# dm646x_cslr_tsif register map
Vendor: Texas Instruments
Peripheral module from a debugger description file.
Registers are 32-bit, access not given, reset 0x0 unless marked. A register's access mark holds for its fields unless they carry their own. Offsets are as the file gives them; lines under a group give offsets from that group; [hi:lo] are bit positions; {n}, {i} and the like mark numbered series; 'fields as' and 'values as' point back to an identical list; <NAME> marks a mode.

## TSIF
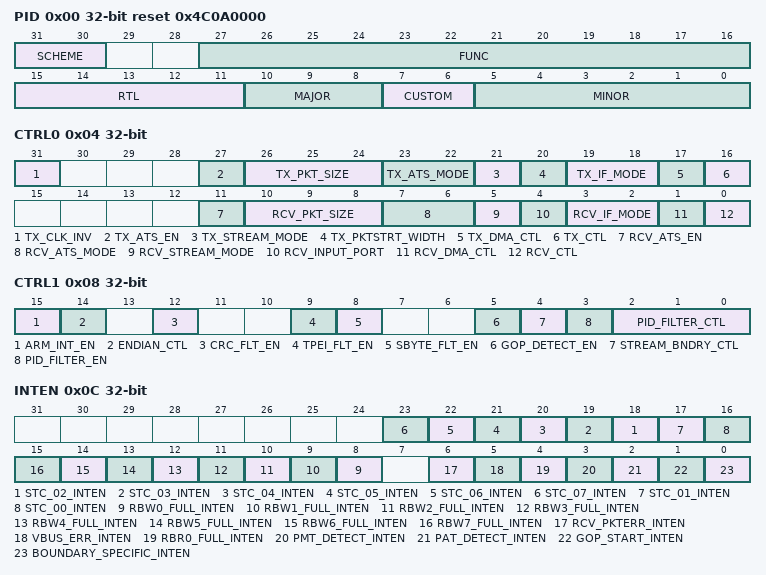
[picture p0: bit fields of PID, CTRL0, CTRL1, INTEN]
0x00 PID reset 0x4C0A0000 — SPIO PID Register
  [31:30] SCHEME ro — Used to distinguish between old scheme and current. Spare bit to encode future schemes. Fixed to be "01
  [27:16] FUNC ro — Function indicates an S/W compatible module family. If there is not level of S/W compatibility, a new Func number (and hence PID) should be assigned
  [15:11] RTL ro — Indicates RTL version
  [10:8] MAJOR ro — Local revision number which should be owned by module designer. This number should be updated for each major design change (such as bug fix, and memory size change etc ). In present design, fixed to be 0
  [7:6] CUSTOM ro — Indicates a special version for a particular device. Consequence of use may avoid use of standard chip support library (CSL). In this module, fixed to be 0.
  [5:0] MINOR ro — Local revision number which should be owned by module designer. This number should be updated for each small design change. In present design, fixed to be 0.
0x04 CTRL0 — SPIO Control Register 0
  [31] TX_CLK_INV rw — This bit controls output timing of transmit clock 0 : Data will output at falling edge of transmit clock(default) 1 : Data will output at rising edge of transmit clock Note that this bit should not be changed during transmit function is enabled
    0=INACTIVATE (Data will output at falling edge of transmit clock(default)); 1=ACTIVATE (Data will output at rising edge of transmit clock)
  [27] TX_ATS_EN rw — This bit is effective when bit[21] = 0 (non-TS mode), and enables time stamp controls with ATS in non-TS packet 0 : Inactivate 1: Activate
    0=INACTIVATE (Interrupt inactivated); 1=ACTIVATE (Interrupt activated)
  [26:24] TX_PKT_SIZE rw — This bit is effective when bit[21] = 0 (non-TS mode), and defines unit data size in non-TS mode. 000 : 200 bytes per packet 001 : 208 bytes per packet 010 : 216 bytes per packet 011 : 224 bytes per packet 100 : 232 bytes per packet 101 : 240 bytes per packet 110 : 248 bytes per packet 111 : 256 bytes per packet
    0=BYTE_200 (200 bytes per packet); 1=BYTE_208 (208 bytes per packet); 2=BYTE_216 (216 bytes per packet); 3=BYTE_224 (224 bytes per packe); 4=BYTE_232 (232 bytes per packe); 5=BYTE_240 (240 bytes per packe); 6=BYTE_248 (248 bytes per packe); 7=BYTE_256 (256 bytes per packe)
  [23:22] TX_ATS_MODE rw — Tx ATS check 00 : outgoing packet has 188 byte 01 : outgoing packet has 192 byte 10 : Reserved 11 : Reserved
    0=OUT_188 (Outgoing packet has 188 byte); 1=OUT_192 (Outgoing packet has 192 byte)
  [21] TX_STREAM_MODE rw — TS mode selection 0:Non TS mode 1:TS mode
    0=TS_INACTIVE (Non TS mode); 1=TS_ACTIVE (TS mode)
  [20] TX_PKTSTRT_WIDTH rw — This bit controls pulse width of Packet start(spio_data_strt_o) in serial mode 0 : 1 cycle width of str_tx_clk_o (default) 1 : 8 cycle width of str_tx_clk_o
    0=CLKWIDTH_1 (1 cycle width of str_tx_clk_o); 1=CLKWIDTH_8 (8 cycle width of str_tx_clk_o)
  [19:18] TX_IF_MODE rw — TX Interface selection 0: Serial interface with synchronous interface 1: Serial interface with asynchronous interface 2: Parallel interface with synchronous interface 3: Parallel interface with asynchronous interface
    0=SER_SYN (Serial synchronous interface); 1=SER_ASYN (Serial asynchronous interface); 2=PAR_SYN (Parallel synchronous interface); 3=PAR_ASYN (Parallel asynchronous interface)
  [17] TX_DMA_CTL rw — Control register for DMA 0:Internal DMA read access disable 1:Internal DMA read access enable
    0=DISABLE (DMA read access disable); 1=ENABLE (DMA read access enable)
  [16] TX_CTL rw — SPIO Transmitter activation 0:SPIO transmitter to be inactivated 1:SPIO transmitter to be activated
    0=INACTIVATE (SPIO transmitter to be inactivated); 1=ACTIVATE (SPIO transmitter to be activated)
  [11] RCV_ATS_EN rw — This bit is effective when bit[21] = 0 (non-TS mode), and enables time stamp controls with ATS in non-TS packet 0 : Inactivate 1: Activate
    values as TX_ATS_EN
  [10:8] RCV_PKT_SIZE rw — This bit is effective when bit[21] = 0 (non-TS mode), and defines unit data size in non-TS mode. 000 : 200 bytes per packet 001 : 208 bytes per packet 010 : 216 bytes per packet 011 : 224 bytes per packet 100 : 232 bytes per packet 101 : 240 bytes per packet 110 : 248 bytes per packet 111 : 256 bytes per packet
    values as TX_PKT_SIZE
  [7:6] RCV_ATS_MODE rw — Tx ATS check 00 : Nothing to do with incoming data (192 byte) 01 : add res to incoming data (188 byte) 10 : change ATS of Incomming data 11 : Add ATS to incoming data
    0=IN_192 (incoming packet has 192 byte); 1=IN_188 (incoming packet has 188 byte); 2=CHANGE_192 (Change ATS of Incomming data); 3=ADD_188 (Add ATS to incoming data)
  [5] RCV_STREAM_MODE rw — TS mode selection 0:Non TS mode 1:TS mode
    0=TS_INACTIVE (Non TS mode); 1=TS_ACTIVE (TS mode)
  [4] RCV_INPUT_PORT rw — Stream data source 0:Stream source data comes from stream I/F 1:Stream source data comes from DMA I/F
    0=STR_IF (From stream I/F); 1=DMA_IF (From DMA I/F)
  [3:2] RCV_IF_MODE rw — RCV Interface selection 0: Serial interface with synchronous interface 1: Serial interface with asynchronous interface 2: Parallel interface with synchronous interface 3: Parallel interface with asynchronous interface
    values as TX_IF_MODE
  [1] RCV_DMA_CTL rw — Control register for DMA 0:Internal DMA read access disable 1:Internal DMA read access enable
    values as TX_DMA_CTL
  [0] RCV_CTL rw — SPIO Transmitter activation 0:SPIO transmitter to be inactivated 1:SPIO transmitter to be activated
    values as TX_CTL
0x08 CTRL1 — SPIO Control Register 1
  [15] ARM_INT_EN rw — Interrupt activation control register 0 : Inactivate 1: Activate
    values as CTRL0.TX_ATS_EN
  [14] ENDIAN_CTL rw — This bit selects storage data format into SDRAM 0 : 32bit Little endian 1: 64 bit width Little endian
    0=BIT_32 (32bit Little endian); 1=BIT_64 (64 bit width Little endian)
  [12] CRC_FLT_EN rw — This bit enables crc check for PAT/PMT parsing when PID_filter_en is enabled. The error packet will be ignored. 0 : crc flt disable 1 : crc flt enable
    0=INACTIVE (crc flt disable); 1=ACTIVE (crc flt enable)
  [9] TPEI_FLT_EN rw — This bit enables filtering transport error indicator = 1 in TS header when PID_filter_en is enabled. The error packet will be ignored. 0 : tpei flt disable 1 : tpei flt enable
    0=INACTIVE (tpei flt disable); 1=ACTIVE (tpei flt enable)
  [8] SBYTE_FLT_EN rw — This bit enables filtering sync byte error in TS header when PID_filter_en is enabled. The error packet will be ignored. 0 : sbyte flt disable 1 : sbyte flt enable
    0=INACTIVE (sbyte flt disable); 1=ACTIVE (sbyte flt enable)
  [5] GOP_DETECT_EN rw — This bit enables detection of GOP start packet with following conditions 0 : Inactivate 1: Activate
    values as CTRL0.TX_ATS_EN
  [4] STREAM_BNDRY_CTL rw — Stream Boundary detect 0:use DIT to detect 1: use user specific packet to detect
    0=DIT (use DIT to detect); 1=USER (user packet to detect)
  [3] PID_FILTER_EN rw — PID filter selection 0:PID filter inactivated 1: PID filter Activated
    0=INACTIVATE (PID filter Inactivated); 1=ACTIVATE (PID filter activated)
  [2:0] PID_FILTER_CTL rw — PID filter performance mode 000 : Full manual mode 001 : Semi-automatic mode-A 010 : Semi-automatic mode-B 011 : Full-automatic mode 100 - 111 : Reserved
    0=FULL_MAN (Full manual mode); 1=SEMI_A (Semi-automatic mode-A); 2=SEMI_B (Semi-automatic mode-B); 3=FULL_AUT (Full-automatic mode)
0x0C INTEN — SPIO Interrupt enable Register
  [all] fields
    0=DISABLE (Interrupt Disable); 1=ENABLE (Interrupt Enable)
  [n+16] STC_{n:02}_INTEN rw (n=2..7) — Interrupt condition and detection enable register bit[{n+16}] 0: disable 1: enable
  [17] STC_01_INTEN rw — Interrupt condition and detection enable register bit17] 0: disable 1: enable
  [16] STC_00_INTEN rw — Interrupt condition and detection enable register bit[16] 0: disable 1: enable
  [n+8] RBW{n}_FULL_INTEN rw (n=0..7) — Interrupt condition and detection enable register bit[{n+8}] 0: disable 1: enable
  [6] RCV_PKTERR_INTEN rw — Interrupt condition and detection enable register bit[6] 0: disable 1: enable
  [5] VBUS_ERR_INTEN rw — Interrupt condition and detection enable register bit[5] 0: disable 1: enable
  [4] RBR0_FULL_INTEN rw — Interrupt condition and detection enable register bit[4] 0: disable 1: enable
  [3] PMT_DETECT_INTEN rw — Interrupt condition and detection enable register bit[3] 0: disable 1: enable
  [2] PAT_DETECT_INTEN rw — Interrupt condition and detection enable register bit[2] 0: disable 1: enable
  [1] GOP_START_INTEN rw — Interrupt condition and detection enable register bit[1] 0: disable 1: enable
  [0] BOUNDARY_SPECIFIC_INTEN rw — Interrupt condition and detection enable register bit[0] 0: disable 1: enable
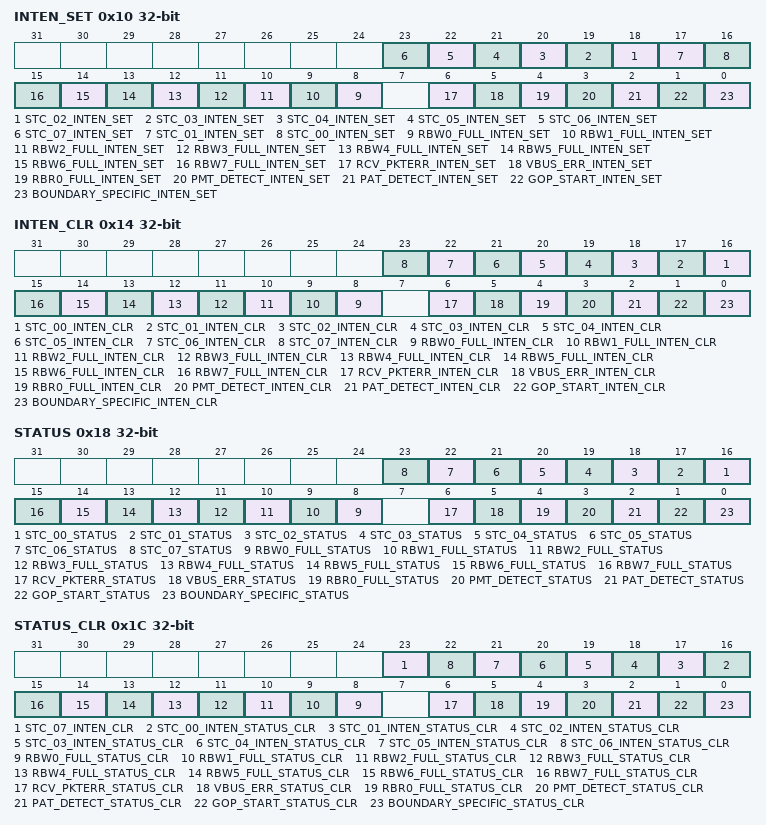
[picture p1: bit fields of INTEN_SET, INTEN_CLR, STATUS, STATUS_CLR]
0x10 INTEN_SET — SPIO Interrupt enable set Register
  [all] fields
    0=DISABLE (Interrupt Disable); 1=ENABLE (Interrupt Enable)
  [n+16] STC_{n:02}_INTEN_SET rw (n=2..7) — Interrupt condition and detection enable register bit[{n+16}] 0: disable 1: enable
  [17] STC_01_INTEN_SET rw — Interrupt condition and detection enable register bit17] 0: disable 1: enable
  [16] STC_00_INTEN_SET rw — Interrupt condition and detection enable register bit[16] 0: disable 1: enable
  [n+8] RBW{n}_FULL_INTEN_SET rw (n=0..7) — Interrupt condition and detection enable register bit[{n+8}] 0: disable 1: enable
  [6] RCV_PKTERR_INTEN_SET rw — Interrupt condition and detection enable register bit[6] 0: disable 1: enable
  [5] VBUS_ERR_INTEN_SET rw — Interrupt condition and detection enable register bit[5] 0: disable 1: enable
  [4] RBR0_FULL_INTEN_SET rw — Interrupt condition and detection enable register bit[4] 0: disable 1: enable
  [3] PMT_DETECT_INTEN_SET rw — Interrupt condition and detection enable register bit[3] 0: disable 1: enable
  [2] PAT_DETECT_INTEN_SET rw — Interrupt condition and detection enable register bit[2] 0: disable 1: enable
  [1] GOP_START_INTEN_SET rw — Interrupt condition and detection enable register bit[1] 0: disable 1: enable
  [0] BOUNDARY_SPECIFIC_INTEN_SET rw — Interrupt condition and detection enable register bit[0] 0: disable 1: enable
0x14 INTEN_CLR — SPIO Interrupt enable clear Register
  [all] fields
    0=NOCHANGE; 1=INACTIVE (Inactivated)
  [n+16] STC_{n:02}_INTEN_CLR wo (n=0..7) — Interrupt condition and detection enable register bit[{n+16}] 0: No change 1: inactivated
  [n+8] RBW{n}_FULL_INTEN_CLR wo (n=0..7) — Interrupt condition and detection enable register bit[{n+8}] 0: No change 1: inactivated
  [6] RCV_PKTERR_INTEN_CLR wo — Interrupt condition and detection enable register bit[6] 0: No change 1: inactivated
  [5] VBUS_ERR_INTEN_CLR wo — Interrupt condition and detection enable register bit[5] 0: No change 1: inactivated
  [4] RBR0_FULL_INTEN_CLR wo — Interrupt condition and detection enable register bit[4] 0: No change 1: inactivated
  [3] PMT_DETECT_INTEN_CLR wo — Interrupt condition and detection enable register bit[3] 0: No change 1: inactivated
  [2] PAT_DETECT_INTEN_CLR wo — Interrupt condition and detection enable register bit[2] 0: No change 1: inactivated
  [1] GOP_START_INTEN_CLR wo — Interrupt condition and detection enable register bit[1] 0: No change 1: inactivated
  [0] BOUNDARY_SPECIFIC_INTEN_CLR wo — Interrupt condition and detection enable register bit[0] 0: No change 1: inactivated
0x18 STATUS — SPIO Interrupt status Register
  [n+16] STC_{n:02}_STATUS ro (n=0..7) — Reflecting interrupt status that STC counter value has reached to configured value of STC interrupt entry counter register on entry number-{n} ({0x22+n}).
  [n+8] RBW{n}_FULL_STATUS ro (n=0..7) — Reflecting interrupt status that SDRAM writing address on ring buffer write channel {n} has reached pointer address configure by ARM via register.
  [6] RCV_PKTERR_STATUS ro — Reflecting interrupt status for receive packet status error. Please refer to RCV_pkt_err register for more details
  [5] VBUS_ERR_STATUS ro — Reflecting interrupt status for VBUS write status error. Please refer to VBUS_W_STATUS register for more details.
  [4] RBR0_FULL_STATUS ro — Reflecting interrupt status that SDRAM reading address on ring buffer read channel 0 has reached pointer address configure by ARM via register.
  [3] PMT_DETECT_STATUS ro — Reflecting interrupt status for detection of new PMT data.
  [2] PAT_DETECT_STATUS ro — Reflecting interrupt status for detection of new PAT data.
  [1] GOP_START_STATUS ro — SPIO module detects GOP start packet
  [0] BOUNDARY_SPECIFIC_STATUS ro — Reflecting interrupt status for host due to detection of specific word which is implemented at dividing point (boundary) of program data in transferred TS data
0x1C STATUS_CLR — SPIO Interrupt status clear Register
  [all] fields
    0=NOCHANGE; 1=INACTIVE (Inactivated)
  [23] STC_07_INTEN_CLR wo — Status clear register for SPIO_status[23] 0: No change 1: inactivated
  [n+16] STC_{n:02}_INTEN_STATUS_CLR wo (n=0..6) — Status clear register for SPIO_status[{n+16}] 0: No change 1: inactivated
  [n+8] RBW{n}_FULL_STATUS_CLR wo (n=0..7) — Status clear register for SPIO_status[{n+8}] 0: No change 1: inactivated
  [6] RCV_PKTERR_STATUS_CLR wo — Status clear register for SPIO_status[6] 0: No change 1: inactivated
  [5] VBUS_ERR_STATUS_CLR wo — Status clear register for SPIO_status[5] 0: No change 1: inactivated
  [4] RBR0_FULL_STATUS_CLR wo — Status clear register for SPIO_status[4] 0: No change 1: inactivated
  [3] PMT_DETECT_STATUS_CLR wo — Status clear register for SPIO_status[3] 0: No change 1: inactivated
  [2] PAT_DETECT_STATUS_CLR wo — Status clear register for SPIO_status[2] 0: No change 1: inactivated
  [1] GOP_START_STATUS_CLR wo — Status clear register for SPIO_status[1] 0: No change 1: inactivated
  [0] BOUNDARY_SPECIFIC_STATUS_CLR wo — Status clear register for SPIO_status[0] 0: No change 1: inactivated
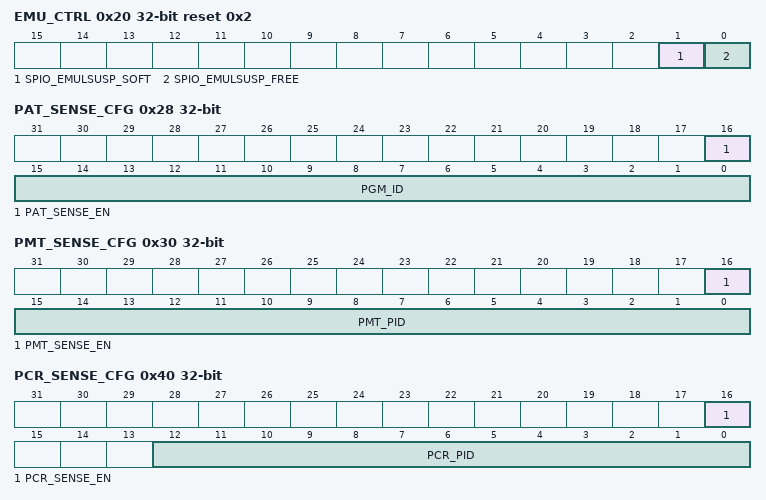
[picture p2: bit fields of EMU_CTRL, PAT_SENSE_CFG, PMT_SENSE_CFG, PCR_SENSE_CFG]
0x20 EMU_CTRL reset 0x2 — SPIO Emulation control Register
  [1] SPIO_EMULSUSP_SOFT ro — This bit defines whether or not a soft or hard stop is initiated whenever the "emususp" is asserted. And this bit is fixed to 1 and read only for SPIO module. SPIO module supports only "soft stop" due to functional restriction related to MPEG-TS (each processing should be executed for each packet as processing unit size).
  [0] SPIO_EMULSUSP_FREE rw — This bit controls whether or not the peripheral will respond to the emulation suspend signal that it has been programmed to monitor. 0: functions based on configuration of "SPIO_emulsusp_soft". 1: ignores any emulation suspend signal (non-stop).
    0=SPIO_EM_S (functions based on configuration of "SPIO_emulsusp_soft".); 1=NONSTOP
0x24 ASYNC_TX_WAIT
  [7:0] PAT_SENSE_EN rw — Wait time between Consecutive packet
0x28 PAT_SENSE_CFG — PAT Sense config Register
  [16] PAT_SENSE_EN rw — Sensing of program association table enable control 0:No PAT filter is active 1: PAT filter is active
    0=INACTIVE (No PAT filter is active); 1=ACTIVE (PAT filter is active)
  [15:0] PGM_ID ro — Filtered program number of PAT
0x2C PAT_STORE_ADDRESS
  [31:3] PAT_STORE_ADD rw — Defines the Start address of SDRAM in which Detected PAT is stored.
0x30 PMT_SENSE_CFG — PMT Sense config Register
  [16] PMT_SENSE_EN rw — Sensing of program map table enable control 0: No PMT filter is active 1: PMT filter is active
    0=INACTIVE (No PMT filter is active); 1=ACTIVE (PMT filter is active)
  [15:0] PMT_PID rw — Filtered PMT_PID
0x34 PMT_STORE_ADDRESS
  [31:3] PMT_STORE_ADD rw — Defines the Start address of SDRAM in which Detected PMT is stored.
0x38 BOUNDARY_SENSING_PACKET_IN reset 0x1FFF
  [12:0] SEAMLESS_BOUNDARY_INPUT_PID rw — This Value defines PID of specific packet which is inserted at boundary of plural programs inside one TS data.
0x3C BSP_STORE_ADDR — Boundary sensing packet in Store address Register
  [31:3] SEAMLESS_BOUNDARY_PKT_STRT_ADDR rw — This register defines start address of SDRAM in which detected boundary sensing packet is stored.
0x40 PCR_SENSE_CFG — PCR SENSE config Register
  [16] PCR_SENSE_EN rw — Sensing of program map table enable control 0:No PCR-PID filter (sensing) is active. 1:PCR-PID filter (sensing) is active
    0=INACTIVATE (PCR-PID inactivated); 1=ACTIVATE (PCR-PID activated)
  [12:0] PCR_PID rw — Filtered PCR_PID. This value is defined by PCR-PID value inserted in PMT
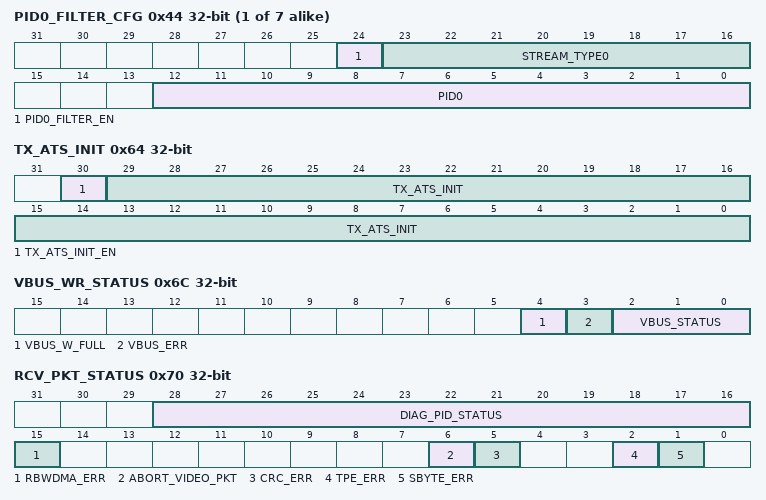
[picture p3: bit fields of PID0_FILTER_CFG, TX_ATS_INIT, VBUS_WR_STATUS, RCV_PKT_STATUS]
{0x44+4i} PID{i}_FILTER_CFG (i=0..6) — PID{i} filter config Register
  [24] PID{i}_FILTER_EN rw — Control register of PID filter with configured PID{i} 0:Filter inactivated 1:Filter activated
    0=INACTIVATE (Filter inactivated); 1=ACTIVATE (Filter activated)
  [23:16] STREAM_TYPE{i} rw — Stream type to be filtered and stored into SDRAM with configured PID{i}
  [12:0] PID{i} rw — PID{i} to be filtered and stored into SDRAM with configured address
0x60 BYPASS_MODE_CFG — Bypass mode config Register
  [24] BYPASS_MODE_EN rw — This bit controls whether to activate or inactivate SDRAM write access on bypass mode 0:Bypass mode inactivated 1:Bypass mode activated
    0=INACTIVATE (Bypass mode inactivated); 1=ACTIVATE (Bypass mode activated)
0x64 TX_ATS_INIT — TX ATS initial value Register
  [30] TX_ATS_INIT_EN rw — ATS Init enabling bit 0:ATS inactivated 1:ATS init activated
    0=INACTIVATE (ATS inactivated); 1=ACTIVATE (ATS init activated)
  [29:0] TX_ATS_INIT rw — Initial value of ATS counter to be loaded with loading pulse generated by configuring above register bit to be 1.
0x68 TX_ATS_MONITOR
  [29:0] TX_ATS_MONITOR ro — Monitoring register with which CPU can read present counter value of ATS counter driven in 27[MHz].
0x6C VBUS_WR_STATUS — VBUS_Write_Status Register
  [4] VBUS_W_FULL ro — Indicates the status for VBUS write status FIFO 0 : Write status FIFO is not occupied 1 : Write status FIFO is full
    0=EMPTY (Write status FIFO is not occupied); 1=FULL (Write status FIFO is full)
  [3] VBUS_ERR ro — Indicates the error for VBUS write status 0 : No error 1 : Error
    0=NOERROR; 1=ERROR
  [2:0] VBUS_STATUS ro — VBUS Write Status 0 : Success 1 : Addressing error 2 : Protection error 3 : Timeout error 4 : RESERVED 5 : Unsupported Addressing Mode error 6 : RESERVED 7 : Exclusive write fail
    0=SUSS (Success); 1=ADDERR (Addressing error); 2=PROTERR (Protection error); 3=TOERR (Timeout error); 5=UAMERR (Unsupported Addressing Mode error); 7=EWFAIL (Exclusive write fail)
0x70 RCV_PKT_STATUS
  [28:16] DIAG_PID_STATUS ro — Indicates pid status of receive error packet. Used for debug purpose.
  [15] RBWDMA_ERR ro — Ring Buffer Write DMA Error in Sync mode. When this bit is "1", received packet is discarded due to count stall or DMA request has not been finished. This bit is effective in only synchronous mode
  [6] ABORT_VIDEO_PKT ro — This bit indicates when vide packet is ignored until GOP detection.This bit is effective when GOP detection is enabled (SPIO_CTRL1.D5)
  [5] CRC_ERR ro — This bit indicates when crc error is occurred in PAT/PMT parsing.This bit is effective when pat_sense_cfg/pmt_sense_cfg is enabled and flt_crc bit (SPIO_CTRL1.D12) is activated. The packet will be ignored and any PID are not updated in Semi-B/Full Auto mode
  [2] TPE_ERR ro — This bit indicates when the packet is ignored with tnasport error Indicator is set 1 in TS header. This bit is effective when PID_filater_en (SPIO_CTRL1.D3) and flt_tpei (SPIO_CTRL1.D9) are enabled
  [1] SBYTE_ERR ro — This bit indicates when the packet is ignored when sync byte is not matched 0x47 in TS header. This bit is effective when PID_filater_en (SPIO_CTRL1.D3) and flt_sbyte (SPIO_CTRL1.D8) are enabled
0x80 STC_INIT_CTRL — STC init control Register
  [0] STC_CNT_RESET wo — User can load the initialize counter value on 0x21 onto STC counter implemented in counter module on the receiver (figure 1.24). This register is write-only register bit and rising edge of this bit is regarded as loading pulse signal of initialize value for STC counter. The initialize value is written in following address 0x21.
0x84 STC_INIT_VAL rw — STC init Value Register
  [31:0] STC_CNT_INIT_VAL — This register defines STC counter initialize value. The configured value is loaded onto the STC counter with reset pulse which is generated by register "STC_init_ctrl (0x20)".
{0x88+4i} STC_INT_ENTRY_{i:02} rw (i=0..7)
  [31:0] STC_INT_ENTRY_{i:02} — This register defines counter value of the STC counter to assert interrupt pulse to CPU. If the STC counter reaches this register value and interrupt condition of this register (please refer to register bit [{i+16}] of 0x03~0x07) is activated, the counter asserts an interrupt pulse to CPU.
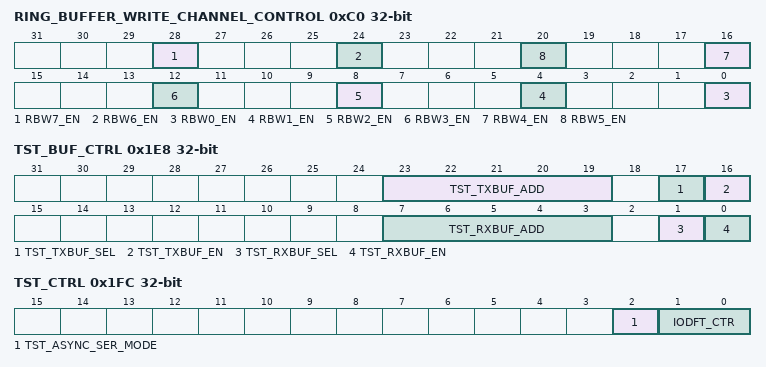
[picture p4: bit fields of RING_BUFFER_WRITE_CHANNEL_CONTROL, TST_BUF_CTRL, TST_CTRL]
0xC0 RING_BUFFER_WRITE_CHANNEL_CONTROL
  [all] fields
    0=INACTIVATE (Ring Buffer inactivated); 1=ACTIVATE (Ring Buffer activated)
  [28] RBW7_EN rw — RBW7 (Ring buffer read channel-0) configuration Register 0:Ring buffer channel-0 inactivated 1:Ring buffer channel-0 activated
  [24] RBW6_EN rw — RBW6 (Ring buffer read channel-6) configuration Register 0:Ring buffer channel-6 inactivated 1:Ring buffer channel-6 activated
  [4n] RBW{n}_EN rw (n=0..5) — RBW{n} (Ring buffer write channel-{n}) configuration Register 0:Ring buffer channel-{n} inactivated 1:Ring buffer channel-{n} activated
0xC4 RING_BUF_WR_CH0_START_ADDR — Ring buffer write channel-0 start address Register
  [31:3] RBW0_STRT_ADD rw — Start address of RBW0 (Ring buffer write channel-0)
0xC8 RING_BUF_WR_CH0_END_ADDR — Ring buffer write channel-0 end address Register
  [31:3] RBW0_END_ADD rw — End address of RBW0 (Ring buffer write channel-0)
0xCC RING_BUF_WR_CH0_RD_POINT_ADDR — Ring buffer write channel-0 read pointer address Register
  [31:3] RBW0_RP_ADD rw — Read pointer address of RBW0 (Ring buffer write channel-0)
0xD0 RING_BUF_WR_CH0_SUB — Ring buffer write channel-0 subtraction Register
  [31:3] RBW0_SUB rw — Distance of temporal read address pointer from read pointer address for RBW0 (Ring buffer write channel 0)
0xD4 RING_BUF_WR_CH0_PR_ADDR ro — Ring buffer write channel-0 present address Register
  [31:0] RBW0_PRST_ADD — Present writing address of RBW0 (Ring buffer write channel-0)
{0xC0+0x20*i} RING_BUF_WR_CH{i}_START_ADDR (i=1..7) — Ring buffer write channel-{i} start address Register
  [31:3] RBW{i}_STRT_ADD rw — Start address of RBW{i} (Ring buffer write channel-{i})
{0xC4+0x20*i} RING_BUF_WR_CH{i}_END_ADDR (i=1..7) — Ring buffer write channel-{i} end address Register
  [31:3] RBW{i}_END_ADD rw — End address of RBW{i} (Ring buffer write channel-{i})
{0xC8+0x20*i} RING_BUF_WR_CH{i}_RD_POINT_ADDR (i=1..7) — Ring buffer write channel-{i} read pointer address Register
  [31:3] RBW{i}_RP_ADD rw — Read pointer address of RBW{i} (Ring buffer write channel-{i})
{0xCC+0x20*i} RING_BUF_WR_CH{i}_SUB (i=1..7) — Ring buffer write channel-{i} subtraction Register
  [31:3] RBW{i}_SUB rw — Distance of temporal read address pointer from read pointer address for RBW{i} (Ring buffer write channel {i})
{0xD0+0x20*i} RING_BUF_WR_CH{i}_PR_ADDR ro (i=1..5) — Ring buffer write channel-{i} present address Register
  [31:0] RBW{i}_PRST_ADD — Present writing address of RBW{i} (Ring buffer write channel-{i})
0x190 RING_BUF_WR_CH6_PR_ADDR rw — Ring buffer write channel-6 present address Register
  [31:0] RBW6_PRST_ADD — Present writing address of RBW6 (Ring buffer write channel-6)
0x1B0 RING_BUF_WR_CH7_PR_ADDR ro — Ring buffer write channel-6 present address Register
  [31:0] RBW7_PRST_ADD — Present writing address of RBW7 (Ring buffer write channel-7)
0x1C0 RING_BUF_RD_CH_CTL — Ring buffer Read channel control Register
  [0] RBR0_EN rw — Ring Buffer channel 0 activating Register 0: Read channel - 0 Inactive 1: Read channel - 0 active
    0=INACTIVE (Read channel - 0 Inactive); 1=ACTIVE (Read channel - 0 active)
0x1C4 RING_BUF_RD_CH0_START_ADDR — Ring buffer Read channel-0 start address Register
  [31:3] RBR0_STRT_ADD rw — Start address of RBR0 (Ring buffer read channel-0)
0x1C8 RING_BUF_RD_CH0_END_ADDR — Ring buffer read channel-0 end address Register
  [31:3] RBR0_END_ADD rw — End address of RBR0 (Ring buffer read channel-0)
0x1CC RING_BUF_RD_CH0_WR_POINT_ADDR — Ring buffer read channel-0 write pointer address Register
  [31:3] RBR0_RP_ADD rw — Read pointer address of RBR0 (Ring buffer read channel-0)
0x1D0 RING_BUF_RD_CH0_SUB — Ring buffer read channel-0 subtraction Register
  [31:3] RBR0_SUB rw — Distance of temporal write address pointer from write pointer address for RBR0 (Ring buffer read channel 0)
0x1D4 RING_BUF_RD_CH0_PR_ADDR ro — Ring buffer read channel-0 present address Register
  [31:0] RBR0_PRST_ADD — Present writing address of RBR0 (Ring buffer read channel-0)
0x1D8 PKT_CNT_VAL ro — Packet counter value Register
  [31:0] PKT_CNT — Packet count value reflected to this register
0x1E8 TST_BUF_CTRL — TST buf control register
  [23:19] TST_TXBUF_ADD rw — Tx Buffer Memory Address
  [17] TST_TXBUF_SEL rw — Tx Buffer Memory Select. 0 : Buffer 0 1 : Buffer 1
    0=BUFF0 (Buffer 0); 1=BUFF1 (Buffer 1)
  [16] TST_TXBUF_EN rw — Enable for direct access mode to Tx Buffer Memory 0 : Normal function 1 : Direct Access mode for test
    0=INACTIVE (Normal function); 1=ACTIVE (Direct Access mode for test)
  [7:3] TST_RXBUF_ADD rw — Rx Buffer Memory Address
  [1] TST_RXBUF_SEL rw — Rx Buffer Memory Select. 0 : Buffer 0 1 : Buffer 1
    0=BUFF0 (Buffer 0); 1=BUFF1 (Buffer 1)
  [0] TST_RXBUF_EN rw — Enable for direct access mode to Rx Buffer Memory 0 : Normal function 1 : Direct Access mode for test
    values as TST_TXBUF_EN
0x1EC TST_RXBUF_U rw — TST Rx buff Register (Upper)
  [31:0] TD_63_32 — Upper 32 bits test access register in Memory direct access mode
0x1F0 TST_RXBUF_L rw — TST Rx buff Register (Lower)
  [31:0] TD_31_0 — Lower 32 bits test access register in Memory direct access mode
0x1F4 TST_TXBUF_U rw — TST Tx buff Register (Upper)
  fields as TST_RXBUF_U
0x1F8 TST_TXBUF_L rw — TST Tx buff Register (Lower)
  fields as TST_RXBUF_L
0x1FC TST_CTRL — TST control register
  [2] TST_ASYNC_SER_MODE rw — Async serial mode select for IODFT testing. 0 : Normal Interface mode 1 : IOFDT Async serial interface mode
    0=NORMAL (Normal Interface mode); 1=ASY_INPUT (IOFDT Async serial interface mode)
  [1:0] IODFT_CTR rw — Control input data mode for IODFT mode 00 : Normal function mode 01 : Use normal inputs for IODFT testing 10 : Use internal loop back for IODFT testing 11 : Use test inputs for IODFT testing
    0=NORMAL (Normal function mode); 1=N_INPUT (Use normal inputs for IODFT testing); 2=LOOP_IN (Use internal loop back for IODFT testing); 3=TEST_IN (Use test inputs for IODFT testing)
